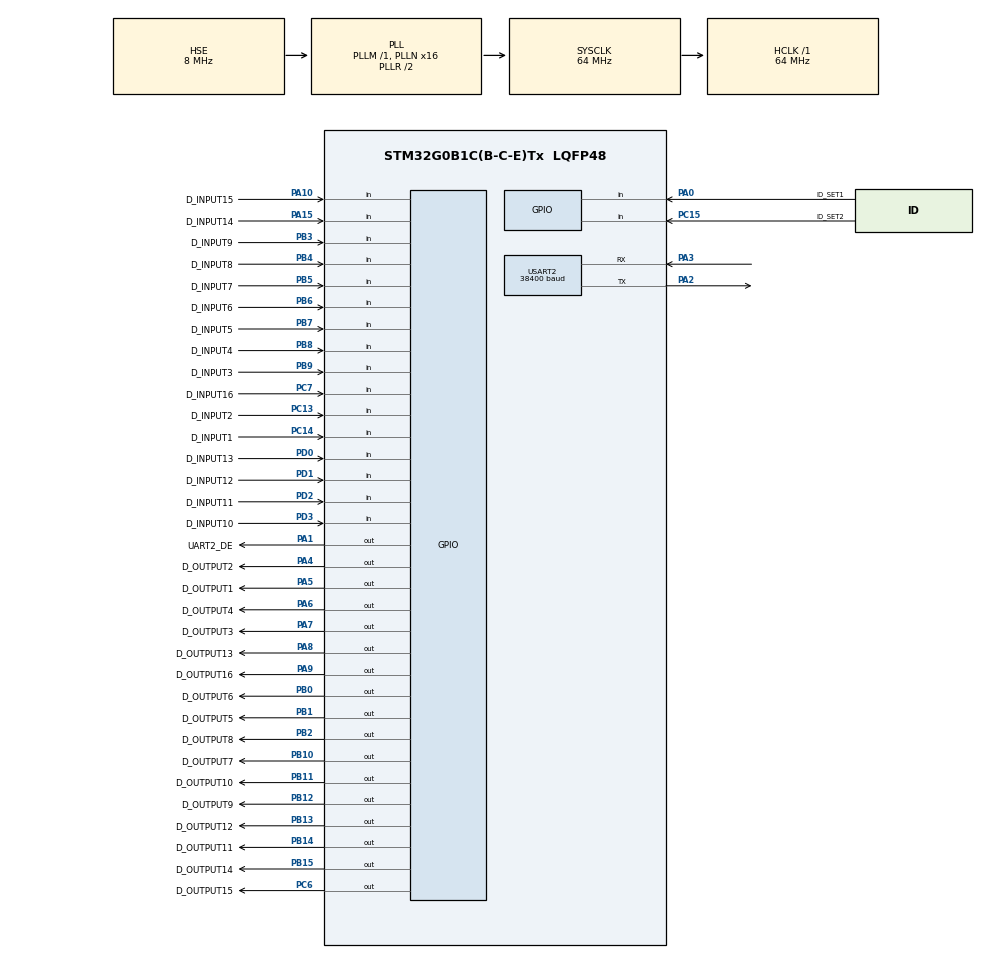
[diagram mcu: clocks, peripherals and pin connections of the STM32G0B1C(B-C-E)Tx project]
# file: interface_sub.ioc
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Dma.Request0=USART2_RX
Dma.USART2_RX.0.Direction=DMA_PERIPH_TO_MEMORY
Dma.USART2_RX.0.EventEnable=DISABLE
Dma.USART2_RX.0.Instance=DMA1_Channel1
Dma.USART2_RX.0.MemDataAlignment=DMA_MDATAALIGN_BYTE
Dma.USART2_RX.0.MemInc=DMA_MINC_ENABLE
Dma.USART2_RX.0.Mode=DMA_NORMAL
Dma.USART2_RX.0.PeriphDataAlignment=DMA_PDATAALIGN_BYTE
Dma.USART2_RX.0.PeriphInc=DMA_PINC_DISABLE
Dma.USART2_RX.0.Polarity=HAL_DMAMUX_REQ_GEN_RISING
Dma.USART2_RX.0.Priority=DMA_PRIORITY_VERY_HIGH
Dma.USART2_RX.0.RequestNumber=1
Dma.USART2_RX.0.SignalID=NONE
Dma.USART2_RX.0.SyncEnable=DISABLE
Dma.USART2_RX.0.SyncPolarity=HAL_DMAMUX_SYNC_NO_EVENT
Dma.USART2_RX.0.SyncRequestNumber=1
Dma.USART2_RX.0.SyncSignalID=NONE
FREERTOS.Tasks01=defaultTask,24,128,StartDefaultTask,Default,NULL,Dynamic,NULL,NULL
FREERTOS.configGENERATE_RUN_TIME_STATS=1
FREERTOS.configTOTAL_HEAP_SIZE=12072
FREERTOS.configUSE_NEWLIB_REENTRANT=1
FREERTOS.configUSE_STATS_FORMATTING_FUNCTIONS=1
Mcu.Family=STM32G0
Mcu.Name=STM32G0B1C(B-C-E)Tx
Mcu.Package=LQFP48
NVIC.DMA1_Channel1_IRQn=true\:3\:0\:false\:false\:true\:true\:false\:true\:true
NVIC.TIM16_FDCAN_IT0_IRQn=true\:3\:0\:true\:false\:true\:false\:false\:true\:true
NVIC.TimeBase=TIM16_FDCAN_IT0_IRQn
NVIC.TimeBaseIP=TIM16
NVIC.USART2_LPUART2_IRQn=true\:3\:0\:false\:false\:true\:true\:true\:true\:true
PA0.GPIO_Label=ID_SET1
PA0.Signal=GPIO_Input
PA1.GPIO_Label=UART2_DE
PA1.Signal=GPIO_Output
PA10.GPIO_Label=D_INPUT15
PA10.Signal=GPIO_Input
PA11.Signal=USB_DM
PA12.Signal=USB_DP
PA13.Mode=Serial_Wire
PA13.Signal=SYS_SWDIO
PA14-BOOT0.Mode=Serial_Wire
PA14-BOOT0.Signal=SYS_SWCLK
PA15.GPIO_Label=D_INPUT14
PA15.Signal=GPIO_Input
PA2.GPIO_Speed=GPIO_SPEED_FREQ_VERY_HIGH
PA2.Mode=Asynchronous
PA2.Signal=USART2_TX
PA3.GPIO_Speed=GPIO_SPEED_FREQ_VERY_HIGH
PA3.Mode=Asynchronous
PA3.Signal=USART2_RX
PA4.GPIO_Label=D_OUTPUT2
PA4.Signal=GPIO_Output
PA5.GPIO_Label=D_OUTPUT1
PA5.Signal=GPIO_Output
PA6.GPIO_Label=D_OUTPUT4
PA6.Signal=GPIO_Output
PA7.GPIO_Label=D_OUTPUT3
PA7.Signal=GPIO_Output
PA8.GPIO_Label=D_OUTPUT13
PA8.Signal=GPIO_Output
PA9.GPIO_Label=D_OUTPUT16
PA9.Signal=GPIO_Output
PB0.GPIO_Label=D_OUTPUT6
PB0.Signal=GPIO_Output
PB1.GPIO_Label=D_OUTPUT5
PB1.Signal=GPIO_Output
PB10.GPIO_Label=D_OUTPUT7
PB10.Signal=GPIO_Output
PB11.GPIO_Label=D_OUTPUT10
PB11.Signal=GPIO_Output
PB12.GPIO_Label=D_OUTPUT9
PB12.Signal=GPIO_Output
PB13.GPIO_Label=D_OUTPUT12
PB13.Signal=GPIO_Output
PB14.GPIO_Label=D_OUTPUT11
PB14.Signal=GPIO_Output
PB15.GPIO_Label=D_OUTPUT14
PB15.Signal=GPIO_Output
PB2.GPIO_Label=D_OUTPUT8
PB2.Signal=GPIO_Output
PB3.GPIO_Label=D_INPUT9
PB3.Signal=GPIO_Input
PB4.GPIO_Label=D_INPUT8
PB4.Signal=GPIO_Input
PB5.GPIO_Label=D_INPUT7
PB5.Signal=GPIO_Input
PB6.GPIO_Label=D_INPUT6
PB6.Signal=GPIO_Input
PB7.GPIO_Label=D_INPUT5
PB7.Signal=GPIO_Input
PB8.GPIO_Label=D_INPUT4
PB8.Signal=GPIO_Input
PB9.GPIO_Label=D_INPUT3
PB9.Signal=GPIO_Input
PC13.GPIO_Label=D_INPUT2
PC13.Signal=GPIO_Input
PC14-OSC32_IN\ (PC14).GPIO_Label=D_INPUT1
PC14-OSC32_IN\ (PC14).Signal=GPIO_Input
PC15-OSC32_OUT\ (PC15).GPIO_Label=ID_SET2
PC15-OSC32_OUT\ (PC15).Signal=GPIO_Input
PC6.GPIO_Label=D_OUTPUT15
PC6.Signal=GPIO_Output
PC7.GPIO_Label=D_INPUT16
PC7.Signal=GPIO_Input
PD0.GPIO_Label=D_INPUT13
PD0.Signal=GPIO_Input
PD1.GPIO_Label=D_INPUT12
PD1.Signal=GPIO_Input
PD2.GPIO_Label=D_INPUT11
PD2.Signal=GPIO_Input
PD3.GPIO_Label=D_INPUT10
PD3.Signal=GPIO_Input
PF0-OSC_IN\ (PF0).Mode=HSE-External-Oscillator
PF0-OSC_IN\ (PF0).Signal=RCC_OSC_IN
PF1-OSC_OUT\ (PF1).Mode=HSE-External-Oscillator
PF1-OSC_OUT\ (PF1).Signal=RCC_OSC_OUT
ProjectManager.HeapSize=0x200
ProjectManager.StackSize=0x400
ProjectManager.TargetToolchain=STM32CubeIDE
RCC.ADCFreq_Value=64000000
RCC.AHBFreq_Value=64000000
RCC.CortexFreq_Value=64000000
RCC.EXTERNAL_CLOCK_VALUE=48000
RCC.HCLKFreq_Value=64000000
RCC.HSE_VALUE=8000000
RCC.HSI48_VALUE=48000000
RCC.HSI_VALUE=16000000
RCC.LSE_VALUE=32768
RCC.PLLN=16
RCC.PLLSourceVirtual=RCC_PLLSOURCE_HSE
RCC.PREFETCH_ENABLE=1
RCC.SYSCLKFreq_VALUE=64000000
RCC.SYSCLKSource=RCC_SYSCLKSOURCE_PLLCLK
RCC.USBFreq_Value=48000000
RCC.VCOOutputFreq_Value=128000000
USART2.BaudRate=38400
USART2.DMADisableonRxErrorParam=ADVFEATURE_DMA_ENABLEONRXERROR
USART2.FIFOMode=FIFOMODE_DISABLE
USART2.OverrunDisableParam=ADVFEATURE_OVERRUN_ENABLE
USART2.VirtualMode-Asynchronous=VM_ASYNC
VP_FREERTOS_VS_CMSIS_V2.Mode=CMSIS_V2
VP_SYS_VS_DBSignals.Mode=DisableDeadBatterySignals
VP_SYS_VS_tim16.Mode=TIM16
VP_TIM7_VS_ClockSourceINT.Mode=Enable_Timer
board=custom

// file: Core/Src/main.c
/* USER CODE BEGIN Header */
/**
  ******************************************************************************
  * @file           : main.c
  * @brief          : Main program body
  ******************************************************************************
  * @attention
  *
  * Copyright (c) 2025 STMicroelectronics.
  * All rights reserved.
  *
  * This software is licensed under terms that can be found in the LICENSE file
  * in the root directory of this software component.
  * If no LICENSE file comes with this software, it is provided AS-IS.
  *
  ******************************************************************************
  */

//TODO id 설정시 동작하게, 주소가 40000번지부터임 근데 지금은 0,1부터 시작함

/* USER CODE END Header */
#include "main.h"
#include "cmsis_os.h"
#include "usb_device.h"

/* USER CODE BEGIN Includes */
#include "a_application.h"
#include "a_usb_test.h"
/* USER CODE END Includes */

TIM_HandleTypeDef htim7;

UART_HandleTypeDef huart2;
DMA_HandleTypeDef hdma_usart2_rx;

/* Definitions for defaultTask */
osThreadId_t defaultTaskHandle;
const osThreadAttr_t defaultTask_attributes = {
  .name = "defaultTask",
  .priority = (osPriority_t) osPriorityNormal,
  .stack_size = 128 * 4
};

void SystemClock_Config(void);
static void MX_GPIO_Init(void);
static void MX_DMA_Init(void);
static void MX_USART2_UART_Init(void);
static void MX_TIM7_Init(void);
void StartDefaultTask(void *argument);

int main(void)
{

  /* MCU Configuration--------------------------------------------------------*/

  /* Reset of all peripherals, Initializes the Flash interface and the Systick. */
  HAL_Init();

  /* Configure the system clock */
  SystemClock_Config();

  /* Initialize all configured peripherals */
  MX_GPIO_Init();
  MX_DMA_Init();
  MX_USART2_UART_Init();
  MX_TIM7_Init();
  MX_USB_Device_Init();
  /* USER CODE BEGIN 2 */
  DioUsbTest_Init();
  /* USER CODE END 2 */

  /* Init scheduler */
  osKernelInitialize();

  /* Create the thread(s) */
  /* creation of defaultTask */
  defaultTaskHandle = osThreadNew(StartDefaultTask, NULL, &defaultTask_attributes);

  /* USER CODE BEGIN RTOS_THREADS */
  /* add threads, ... */
  InitApplication();
  /* USER CODE END RTOS_THREADS */

  /* Start scheduler */
  osKernelStart();

  /* We should never get here as control is now taken by the scheduler */

  /* Infinite loop */
  while (1)
  {

  }
}

void SystemClock_Config(void)
{
  RCC_OscInitTypeDef RCC_OscInitStruct = {0};
  RCC_ClkInitTypeDef RCC_ClkInitStruct = {0};

  /** Configure the main internal regulator output voltage
  */
  HAL_PWREx_ControlVoltageScaling(PWR_REGULATOR_VOLTAGE_SCALE1);

  /** Initializes the RCC Oscillators according to the specified parameters
  * in the RCC_OscInitTypeDef structure.
  */
  RCC_OscInitStruct.OscillatorType = RCC_OSCILLATORTYPE_HSE;
  RCC_OscInitStruct.HSEState = RCC_HSE_ON;
  RCC_OscInitStruct.PLL.PLLState = RCC_PLL_ON;
  RCC_OscInitStruct.PLL.PLLSource = RCC_PLLSOURCE_HSE;
  RCC_OscInitStruct.PLL.PLLM = RCC_PLLM_DIV1;
  RCC_OscInitStruct.PLL.PLLN = 16;
  RCC_OscInitStruct.PLL.PLLP = RCC_PLLP_DIV2;
  RCC_OscInitStruct.PLL.PLLQ = RCC_PLLQ_DIV2;
  RCC_OscInitStruct.PLL.PLLR = RCC_PLLR_DIV2;
  if (HAL_RCC_OscConfig(&RCC_OscInitStruct) != HAL_OK)
  {
    Error_Handler();
  }

  /** Initializes the CPU, AHB and APB buses clocks
  */
  RCC_ClkInitStruct.ClockType = RCC_CLOCKTYPE_HCLK|RCC_CLOCKTYPE_SYSCLK
                              |RCC_CLOCKTYPE_PCLK1;
  RCC_ClkInitStruct.SYSCLKSource = RCC_SYSCLKSOURCE_PLLCLK;
  RCC_ClkInitStruct.AHBCLKDivider = RCC_SYSCLK_DIV1;
  RCC_ClkInitStruct.APB1CLKDivider = RCC_HCLK_DIV1;

  if (HAL_RCC_ClockConfig(&RCC_ClkInitStruct, FLASH_LATENCY_2) != HAL_OK)
  {
    Error_Handler();
  }
}

static void MX_TIM7_Init(void)
{

  TIM_MasterConfigTypeDef sMasterConfig = {0};

  htim7.Instance = TIM7;
  htim7.Init.Prescaler = 0;
  htim7.Init.CounterMode = TIM_COUNTERMODE_UP;
  htim7.Init.Period = 65535;
  htim7.Init.AutoReloadPreload = TIM_AUTORELOAD_PRELOAD_DISABLE;
  if (HAL_TIM_Base_Init(&htim7) != HAL_OK)
  {
    Error_Handler();
  }
  sMasterConfig.MasterOutputTrigger = TIM_TRGO_RESET;
  sMasterConfig.MasterSlaveMode = TIM_MASTERSLAVEMODE_DISABLE;
  if (HAL_TIMEx_MasterConfigSynchronization(&htim7, &sMasterConfig) != HAL_OK)
  {
    Error_Handler();
  }

}

static void MX_USART2_UART_Init(void)
{

  huart2.Instance = USART2;
  huart2.Init.BaudRate = 38400;
  huart2.Init.WordLength = UART_WORDLENGTH_8B;
  huart2.Init.StopBits = UART_STOPBITS_1;
  huart2.Init.Parity = UART_PARITY_NONE;
  huart2.Init.Mode = UART_MODE_TX_RX;
  huart2.Init.HwFlowCtl = UART_HWCONTROL_NONE;
  huart2.Init.OverSampling = UART_OVERSAMPLING_16;
  huart2.Init.OneBitSampling = UART_ONE_BIT_SAMPLE_DISABLE;
  huart2.Init.ClockPrescaler = UART_PRESCALER_DIV1;
  huart2.AdvancedInit.AdvFeatureInit = UART_ADVFEATURE_NO_INIT;
  if (HAL_UART_Init(&huart2) != HAL_OK)
  {
    Error_Handler();
  }
  if (HAL_UARTEx_SetTxFifoThreshold(&huart2, UART_TXFIFO_THRESHOLD_1_8) != HAL_OK)
  {
    Error_Handler();
  }
  if (HAL_UARTEx_SetRxFifoThreshold(&huart2, UART_RXFIFO_THRESHOLD_1_8) != HAL_OK)
  {
    Error_Handler();
  }
  if (HAL_UARTEx_DisableFifoMode(&huart2) != HAL_OK)
  {
    Error_Handler();
  }

}

static void MX_DMA_Init(void)
{

  /* DMA controller clock enable */
  __HAL_RCC_DMA1_CLK_ENABLE();

  /* DMA interrupt init */
  /* DMA1_Channel1_IRQn interrupt configuration */
  HAL_NVIC_SetPriority(DMA1_Channel1_IRQn, 3, 0);
  HAL_NVIC_EnableIRQ(DMA1_Channel1_IRQn);

}

static void MX_GPIO_Init(void)
{
  GPIO_InitTypeDef GPIO_InitStruct = {0};

  /* GPIO Ports Clock Enable */
  __HAL_RCC_GPIOC_CLK_ENABLE();
  __HAL_RCC_GPIOF_CLK_ENABLE();
  __HAL_RCC_GPIOA_CLK_ENABLE();
  __HAL_RCC_GPIOB_CLK_ENABLE();
  __HAL_RCC_GPIOD_CLK_ENABLE();

  /*Configure GPIO pin Output Level */
  HAL_GPIO_WritePin(GPIOA, UART2_DE_Pin|D_OUTPUT2_Pin|D_OUTPUT1_Pin|D_OUTPUT4_Pin
                          |D_OUTPUT3_Pin|D_OUTPUT13_Pin|D_OUTPUT16_Pin, GPIO_PIN_RESET);

  /*Configure GPIO pin Output Level */
  HAL_GPIO_WritePin(GPIOB, D_OUTPUT6_Pin|D_OUTPUT5_Pin|D_OUTPUT8_Pin|D_OUTPUT7_Pin
                          |D_OUTPUT10_Pin|D_OUTPUT9_Pin|D_OUTPUT12_Pin|D_OUTPUT11_Pin
                          |D_OUTPUT14_Pin, GPIO_PIN_RESET);

  /*Configure GPIO pin Output Level */
  HAL_GPIO_WritePin(D_OUTPUT15_GPIO_Port, D_OUTPUT15_Pin, GPIO_PIN_RESET);

  /*Configure GPIO pins : D_INPUT2_Pin D_INPUT1_Pin ID_SET2_Pin D_INPUT16_Pin */
  GPIO_InitStruct.Pin = D_INPUT2_Pin|D_INPUT1_Pin|ID_SET2_Pin|D_INPUT16_Pin;
  GPIO_InitStruct.Mode = GPIO_MODE_INPUT;
  GPIO_InitStruct.Pull = GPIO_NOPULL;
  HAL_GPIO_Init(GPIOC, &GPIO_InitStruct);

  /*Configure GPIO pins : ID_SET1_Pin D_INPUT15_Pin D_INPUT14_Pin */
  GPIO_InitStruct.Pin = ID_SET1_Pin|D_INPUT15_Pin|D_INPUT14_Pin;
  GPIO_InitStruct.Mode = GPIO_MODE_INPUT;
  GPIO_InitStruct.Pull = GPIO_NOPULL;
  HAL_GPIO_Init(GPIOA, &GPIO_InitStruct);

  /*Configure GPIO pins : UART2_DE_Pin D_OUTPUT2_Pin D_OUTPUT1_Pin D_OUTPUT4_Pin
                           D_OUTPUT3_Pin D_OUTPUT13_Pin D_OUTPUT16_Pin */
  GPIO_InitStruct.Pin = UART2_DE_Pin|D_OUTPUT2_Pin|D_OUTPUT1_Pin|D_OUTPUT4_Pin
                          |D_OUTPUT3_Pin|D_OUTPUT13_Pin|D_OUTPUT16_Pin;
  GPIO_InitStruct.Mode = GPIO_MODE_OUTPUT_PP;
  GPIO_InitStruct.Pull = GPIO_NOPULL;
  GPIO_InitStruct.Speed = GPIO_SPEED_FREQ_LOW;
  HAL_GPIO_Init(GPIOA, &GPIO_InitStruct);

  /*Configure GPIO pins : D_OUTPUT6_Pin D_OUTPUT5_Pin D_OUTPUT8_Pin D_OUTPUT7_Pin
                           D_OUTPUT10_Pin D_OUTPUT9_Pin D_OUTPUT12_Pin D_OUTPUT11_Pin
                           D_OUTPUT14_Pin */
  GPIO_InitStruct.Pin = D_OUTPUT6_Pin|D_OUTPUT5_Pin|D_OUTPUT8_Pin|D_OUTPUT7_Pin
                          |D_OUTPUT10_Pin|D_OUTPUT9_Pin|D_OUTPUT12_Pin|D_OUTPUT11_Pin
                          |D_OUTPUT14_Pin;
  GPIO_InitStruct.Mode = GPIO_MODE_OUTPUT_PP;
  GPIO_InitStruct.Pull = GPIO_NOPULL;
  GPIO_InitStruct.Speed = GPIO_SPEED_FREQ_LOW;
  HAL_GPIO_Init(GPIOB, &GPIO_InitStruct);

  /*Configure GPIO pin : D_OUTPUT15_Pin */
  GPIO_InitStruct.Pin = D_OUTPUT15_Pin;
  GPIO_InitStruct.Mode = GPIO_MODE_OUTPUT_PP;
  GPIO_InitStruct.Pull = GPIO_NOPULL;
  GPIO_InitStruct.Speed = GPIO_SPEED_FREQ_LOW;
  HAL_GPIO_Init(D_OUTPUT15_GPIO_Port, &GPIO_InitStruct);

  /*Configure GPIO pins : D_INPUT13_Pin D_INPUT12_Pin D_INPUT11_Pin D_INPUT10_Pin */
  GPIO_InitStruct.Pin = D_INPUT13_Pin|D_INPUT12_Pin|D_INPUT11_Pin|D_INPUT10_Pin;
  GPIO_InitStruct.Mode = GPIO_MODE_INPUT;
  GPIO_InitStruct.Pull = GPIO_NOPULL;
  HAL_GPIO_Init(GPIOD, &GPIO_InitStruct);

  /*Configure GPIO pins : D_INPUT9_Pin D_INPUT8_Pin D_INPUT7_Pin D_INPUT6_Pin
                           D_INPUT5_Pin D_INPUT4_Pin D_INPUT3_Pin */
  GPIO_InitStruct.Pin = D_INPUT9_Pin|D_INPUT8_Pin|D_INPUT7_Pin|D_INPUT6_Pin
                          |D_INPUT5_Pin|D_INPUT4_Pin|D_INPUT3_Pin;
  GPIO_InitStruct.Mode = GPIO_MODE_INPUT;
  GPIO_InitStruct.Pull = GPIO_NOPULL;
  HAL_GPIO_Init(GPIOB, &GPIO_InitStruct);

  /* USER CODE BEGIN MX_GPIO_Init_2 */

  GPIO_InitStruct.Pin = ID_SET1_Pin;
  GPIO_InitStruct.Mode = GPIO_MODE_INPUT;
  GPIO_InitStruct.Pull = GPIO_PULLDOWN;
  HAL_GPIO_Init(ID_SET1_GPIO_Port, &GPIO_InitStruct);

  GPIO_InitStruct.Pin = ID_SET2_Pin;
  GPIO_InitStruct.Mode = GPIO_MODE_INPUT;
  GPIO_InitStruct.Pull = GPIO_PULLDOWN;
  HAL_GPIO_Init(ID_SET2_GPIO_Port, &GPIO_InitStruct);

  /* USER CODE END MX_GPIO_Init_2 */
}

void StartDefaultTask(void *argument)
{
  /* USER CODE BEGIN 5 */
  /* Infinite loop */
  for(;;)
  {
//    HAL_GPIO_WritePin(D_OUTPUT1_GPIO_Port, D_OUTPUT1_Pin, SET);
//    HAL_GPIO_WritePin(D_OUTPUT2_GPIO_Port, D_OUTPUT2_Pin, SET);
//    HAL_GPIO_WritePin(D_OUTPUT3_GPIO_Port, D_OUTPUT3_Pin, SET);
//    HAL_GPIO_WritePin(D_OUTPUT4_GPIO_Port, D_OUTPUT4_Pin, SET);
//    HAL_GPIO_WritePin(D_OUTPUT5_GPIO_Port, D_OUTPUT5_Pin, SET);
//    HAL_GPIO_WritePin(D_OUTPUT6_GPIO_Port, D_OUTPUT6_Pin, SET);
//    HAL_GPIO_WritePin(D_OUTPUT7_GPIO_Port, D_OUTPUT7_Pin, SET);
//    HAL_GPIO_WritePin(D_OUTPUT8_GPIO_Port, D_OUTPUT8_Pin, SET);
//    HAL_GPIO_WritePin(D_OUTPUT9_GPIO_Port, D_OUTPUT9_Pin, SET);
//    HAL_GPIO_WritePin(D_OUTPUT10_GPIO_Port, D_OUTPUT10_Pin, SET);
//    HAL_GPIO_WritePin(D_OUTPUT11_GPIO_Port, D_OUTPUT11_Pin, SET);
//    HAL_GPIO_WritePin(D_OUTPUT12_GPIO_Port, D_OUTPUT12_Pin, SET);
//    HAL_GPIO_WritePin(D_OUTPUT13_GPIO_Port, D_OUTPUT13_Pin, SET);
//    HAL_GPIO_WritePin(D_OUTPUT14_GPIO_Port, D_OUTPUT14_Pin, SET);
//    HAL_GPIO_WritePin(D_OUTPUT15_GPIO_Port, D_OUTPUT15_Pin, SET);
//    HAL_GPIO_WritePin(D_OUTPUT16_GPIO_Port, D_OUTPUT16_Pin, SET);

    DioUsbTest_Process();
    osDelay(10);
  }
  /* USER CODE END 5 */
}

void HAL_TIM_PeriodElapsedCallback(TIM_HandleTypeDef *htim)
{
  if (htim->Instance == TIM16)
  {
    HAL_IncTick();
  }
}

void Error_Handler(void)
{
  __disable_irq();
  while (1)
  {
  }
}

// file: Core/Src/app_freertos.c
/* USER CODE BEGIN Header */
/**
  ******************************************************************************
  * File Name          : app_freertos.c
  * Description        : Code for freertos applications
  ******************************************************************************
  * @attention
  *
  * Copyright (c) 2025 STMicroelectronics.
  * All rights reserved.
  *
  * This software is licensed under terms that can be found in the LICENSE file
  * in the root directory of this software component.
  * If no LICENSE file comes with this software, it is provided AS-IS.
  *
  ******************************************************************************
  */
/* USER CODE END Header */

#include "FreeRTOS.h"
#include "task.h"
#include "main.h"

/* Hook prototypes */
void configureTimerForRunTimeStats(void);
unsigned long getRunTimeCounterValue(void);

/* USER CODE BEGIN 1 */
/* Functions needed when configGENERATE_RUN_TIME_STATS is on */
__weak void configureTimerForRunTimeStats(void)
{

}

__weak unsigned long getRunTimeCounterValue(void)
{
return 0;
}
/* USER CODE END 1 */
